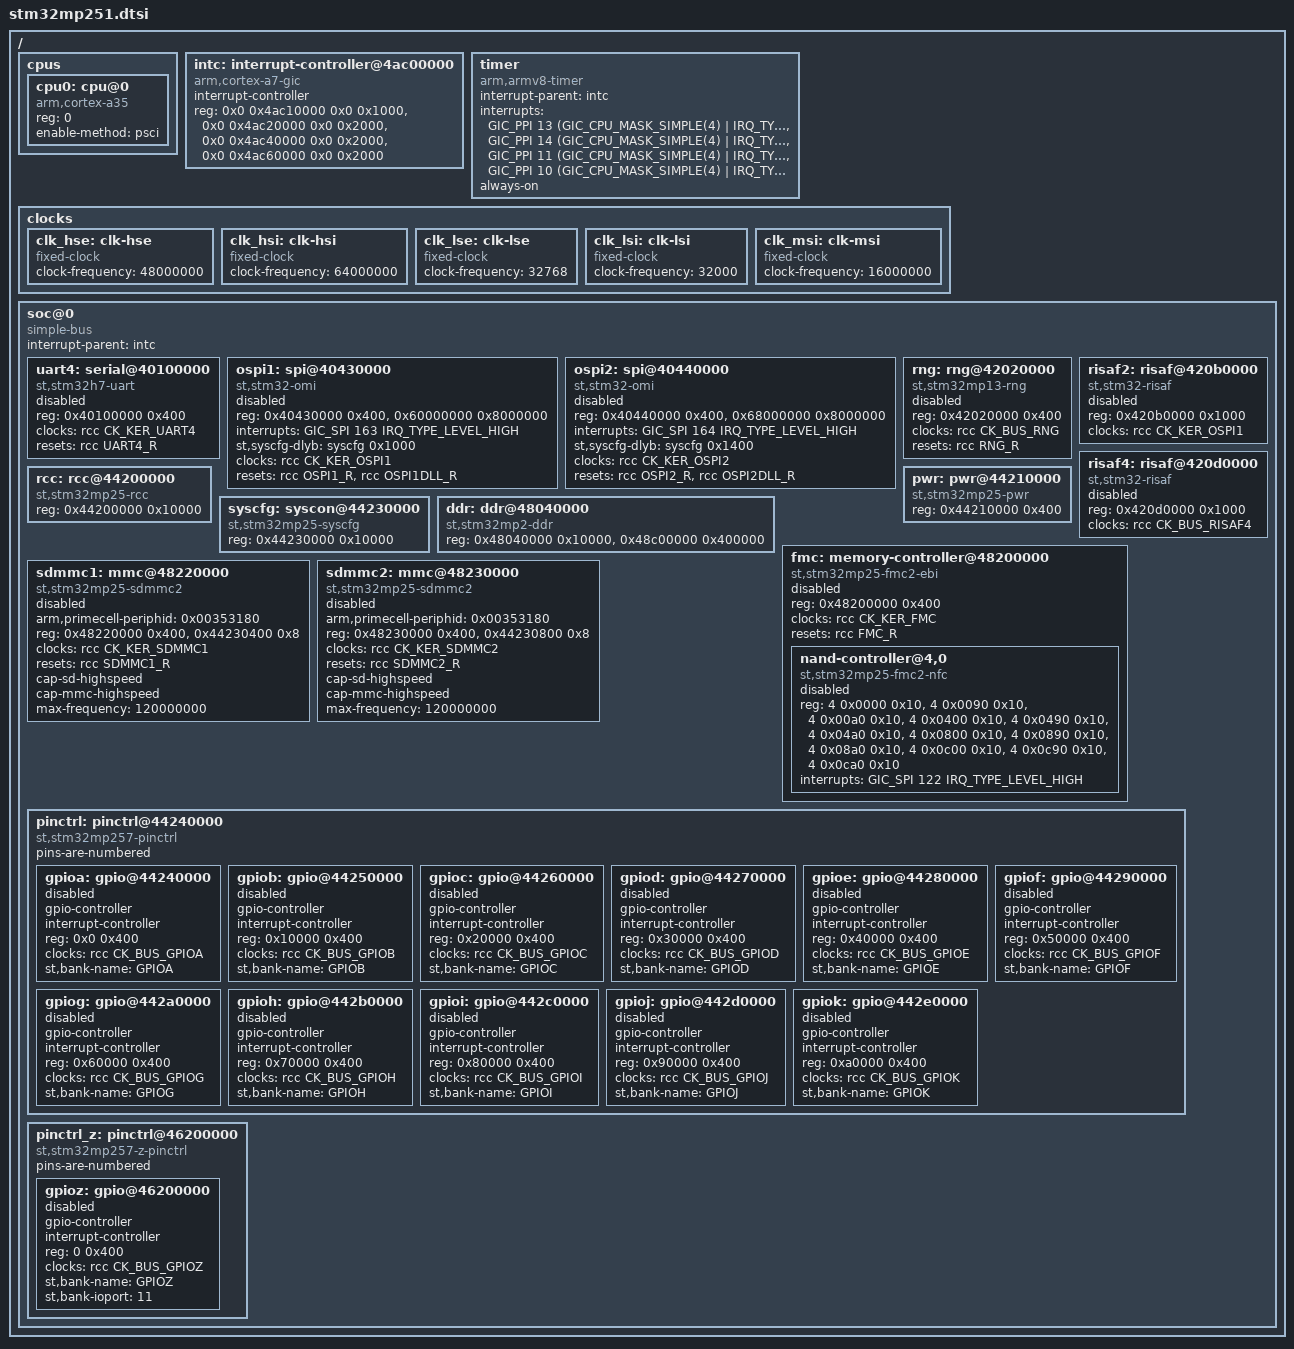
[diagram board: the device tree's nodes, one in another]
// SPDX-License-Identifier: (GPL-2.0+ OR BSD-3-Clause)
/*
 * Copyright (C) STMicroelectronics 2021 - All Rights Reserved
 * Author: Alexandre Torgue <alexandre.torgue@foss.st.com> for STMicroelectronics.
 */

#include <dt-bindings/clock/stm32mp25-clks.h>
#include <dt-bindings/interrupt-controller/arm-gic.h>
#include <dt-bindings/reset/stm32mp25-resets.h>

/ {
	#address-cells = <2>;
	#size-cells = <2>;

	cpus {
		#address-cells = <1>;
		#size-cells = <0>;

		cpu0: cpu@0 {
			compatible = "arm,cortex-a35";
			device_type = "cpu";
			reg = <0>;
			enable-method = "psci";
		};
	};

	intc: interrupt-controller@4ac00000 {
		compatible = "arm,cortex-a7-gic";
		#interrupt-cells = <3>;
		interrupt-controller;
		reg = <0x0 0x4ac10000 0x0 0x1000>,
		      <0x0 0x4ac20000 0x0 0x2000>,
		      <0x0 0x4ac40000 0x0 0x2000>,
		      <0x0 0x4ac60000 0x0 0x2000>;
	};

	timer: timer {
		compatible = "arm,armv8-timer";
		interrupt-parent = <&intc>;
		interrupts = <GIC_PPI 13 (GIC_CPU_MASK_SIMPLE(4) | IRQ_TYPE_LEVEL_LOW)>,
			     <GIC_PPI 14 (GIC_CPU_MASK_SIMPLE(4) | IRQ_TYPE_LEVEL_LOW)>,
			     <GIC_PPI 11 (GIC_CPU_MASK_SIMPLE(4) | IRQ_TYPE_LEVEL_LOW)>,
			     <GIC_PPI 10 (GIC_CPU_MASK_SIMPLE(4) | IRQ_TYPE_LEVEL_LOW)>;
		always-on;
	};

	clocks {
		clk_hse: clk-hse {
			#clock-cells = <0>;
			compatible = "fixed-clock";
			clock-frequency = <48000000>;
		};

		clk_hsi: clk-hsi {
			#clock-cells = <0>;
			compatible = "fixed-clock";
			clock-frequency = <64000000>;
		};

		clk_lse: clk-lse {
			#clock-cells = <0>;
			compatible = "fixed-clock";
			clock-frequency = <32768>;
		};

		clk_lsi: clk-lsi {
			#clock-cells = <0>;
			compatible = "fixed-clock";
			clock-frequency = <32000>;
		};

		clk_msi: clk-msi {
			#clock-cells = <0>;
			compatible = "fixed-clock";
			clock-frequency = <16000000>;
		};
	};

	soc@0 {
		compatible = "simple-bus";
		#address-cells = <1>;
		#size-cells = <1>;
		interrupt-parent = <&intc>;
		ranges = <0x0 0x0 0x0 0x80000000>;

		uart4: serial@40100000 {
			compatible = "st,stm32h7-uart";
			reg = <0x40100000 0x400>;
			clocks = <&rcc CK_KER_UART4>;
			resets = <&rcc UART4_R>;
			status = "disabled";
		};

		ospi1: spi@40430000 {
			compatible = "st,stm32-omi";
			reg = <0x40430000 0x400>, <0x60000000 0x8000000>;
			reg-names = "ospi", "ospi_mm";
			interrupts = <GIC_SPI 163 IRQ_TYPE_LEVEL_HIGH>;
			st,syscfg-dlyb = <&syscfg 0x1000>;
			clocks = <&rcc CK_KER_OSPI1>;
			resets = <&rcc OSPI1_R>, <&rcc OSPI1DLL_R>;
			status = "disabled";
		};

		ospi2: spi@40440000 {
			compatible = "st,stm32-omi";
			reg = <0x40440000 0x400>, <0x68000000 0x8000000>;
			reg-names = "ospi", "ospi_mm";
			interrupts = <GIC_SPI 164 IRQ_TYPE_LEVEL_HIGH>;
			st,syscfg-dlyb = <&syscfg 0x1400>;
			clocks = <&rcc CK_KER_OSPI2>;
			resets = <&rcc OSPI2_R>, <&rcc OSPI2DLL_R>;
			status = "disabled";
		};

		rng: rng@42020000 {
			compatible = "st,stm32mp13-rng";
			reg = <0x42020000 0x400>;
			clocks = <&rcc CK_BUS_RNG>;
			resets = <&rcc RNG_R>;
			status = "disabled";
		};

		risaf2: risaf@420b0000 {
			compatible = "st,stm32-risaf";
			reg = <0x420b0000 0x1000>;
			clocks = <&rcc CK_KER_OSPI1>;
			status = "disabled";
		};

		risaf4: risaf@420d0000 {
			compatible = "st,stm32-risaf";
			reg = <0x420d0000 0x1000>;
			clocks = <&rcc CK_BUS_RISAF4>;
			status = "disabled";
		};

		rcc: rcc@44200000 {
			compatible = "st,stm32mp25-rcc";
			reg = <0x44200000 0x10000>;
			#clock-cells = <1>;
			#reset-cells = <1>;
		};

		pwr: pwr@44210000 {
			compatible = "st,stm32mp25-pwr", "syscon", "simple-mfd";
			reg = <0x44210000 0x400>;
		};

		syscfg: syscon@44230000 {
			compatible = "st,stm32mp25-syscfg", "syscon";
			reg = <0x44230000 0x10000>;
		};

		ddr: ddr@48040000 {
			compatible = "st,stm32mp2-ddr";
			reg = <0x48040000 0x10000>,
			      <0x48c00000 0x400000>;
			status = "okay";
		};

		fmc: memory-controller@48200000 {
			#address-cells = <2>;
			#size-cells = <1>;
			compatible = "st,stm32mp25-fmc2-ebi";
			reg = <0x48200000 0x400>;
			clocks = <&rcc CK_KER_FMC>;
			resets = <&rcc FMC_R>;
			status = "disabled";

			ranges = <0 0 0x70000000 0x04000000>, /* EBI CS 1 */
				 <1 0 0x74000000 0x04000000>, /* EBI CS 2 */
				 <2 0 0x78000000 0x04000000>, /* EBI CS 3 */
				 <3 0 0x7c000000 0x04000000>, /* EBI CS 4 */
				 <4 0 0x48810000 0x00001000>; /* NAND */

			nand-controller@4,0 {
				#address-cells = <1>;
				#size-cells = <0>;
				compatible = "st,stm32mp25-fmc2-nfc";
				reg = <4 0x0000 0x10>,
				      <4 0x0090 0x10>,
				      <4 0x00a0 0x10>,
				      <4 0x0400 0x10>,
				      <4 0x0490 0x10>,
				      <4 0x04a0 0x10>,
				      <4 0x0800 0x10>,
				      <4 0x0890 0x10>,
				      <4 0x08a0 0x10>,
				      <4 0x0c00 0x10>,
				      <4 0x0c90 0x10>,
				      <4 0x0ca0 0x10>;
				interrupts = <GIC_SPI 122 IRQ_TYPE_LEVEL_HIGH>;
				status = "disabled";
			};
		};

		sdmmc1: mmc@48220000 {
			compatible = "st,stm32mp25-sdmmc2", "arm,pl18x", "arm,primecell";
			arm,primecell-periphid = <0x00353180>;
			reg = <0x48220000 0x400>, <0x44230400 0x8>;
			clocks = <&rcc CK_KER_SDMMC1>;
			clock-names = "apb_pclk";
			resets = <&rcc SDMMC1_R>;
			cap-sd-highspeed;
			cap-mmc-highspeed;
			max-frequency = <120000000>;
			status = "disabled";
		};

		sdmmc2: mmc@48230000 {
			compatible = "st,stm32mp25-sdmmc2", "arm,pl18x", "arm,primecell";
			arm,primecell-periphid = <0x00353180>;
			reg = <0x48230000 0x400>, <0x44230800 0x8>;
			clocks = <&rcc CK_KER_SDMMC2>;
			clock-names = "apb_pclk";
			resets = <&rcc SDMMC2_R>;
			cap-sd-highspeed;
			cap-mmc-highspeed;
			max-frequency = <120000000>;
			status = "disabled";
		};

		/*
		 * Break node order to solve dependency probe issue between
		 * pinctrl and exti.
		 */
		pinctrl: pinctrl@44240000 {
			#address-cells = <1>;
			#size-cells = <1>;
			compatible = "st,stm32mp257-pinctrl";
			ranges = <0 0x44240000 0xa0400>;
			pins-are-numbered;

			gpioa: gpio@44240000 {
				gpio-controller;
				#gpio-cells = <2>;
				interrupt-controller;
				#interrupt-cells = <2>;
				reg = <0x0 0x400>;
				clocks = <&rcc CK_BUS_GPIOA>;
				st,bank-name = "GPIOA";
				status = "disabled";
			};

			gpiob: gpio@44250000 {
				gpio-controller;
				#gpio-cells = <2>;
				interrupt-controller;
				#interrupt-cells = <2>;
				reg = <0x10000 0x400>;
				clocks = <&rcc CK_BUS_GPIOB>;
				st,bank-name = "GPIOB";
				status = "disabled";
			};

			gpioc: gpio@44260000 {
				gpio-controller;
				#gpio-cells = <2>;
				interrupt-controller;
				#interrupt-cells = <2>;
				reg = <0x20000 0x400>;
				clocks = <&rcc CK_BUS_GPIOC>;
				st,bank-name = "GPIOC";
				status = "disabled";
			};

			gpiod: gpio@44270000 {
				gpio-controller;
				#gpio-cells = <2>;
				interrupt-controller;
				#interrupt-cells = <2>;
				reg = <0x30000 0x400>;
				clocks = <&rcc CK_BUS_GPIOD>;
				st,bank-name = "GPIOD";
				status = "disabled";
			};

			gpioe: gpio@44280000 {
				gpio-controller;
				#gpio-cells = <2>;
				interrupt-controller;
				#interrupt-cells = <2>;
				reg = <0x40000 0x400>;
				clocks = <&rcc CK_BUS_GPIOE>;
				st,bank-name = "GPIOE";
				status = "disabled";
			};

			gpiof: gpio@44290000 {
				gpio-controller;
				#gpio-cells = <2>;
				interrupt-controller;
				#interrupt-cells = <2>;
				reg = <0x50000 0x400>;
				clocks = <&rcc CK_BUS_GPIOF>;
				st,bank-name = "GPIOF";
				status = "disabled";
			};

			gpiog: gpio@442a0000 {
				gpio-controller;
				#gpio-cells = <2>;
				interrupt-controller;
				#interrupt-cells = <2>;
				reg = <0x60000 0x400>;
				clocks = <&rcc CK_BUS_GPIOG>;
				st,bank-name = "GPIOG";
				status = "disabled";
			};

			gpioh: gpio@442b0000 {
				gpio-controller;
				#gpio-cells = <2>;
				interrupt-controller;
				#interrupt-cells = <2>;
				reg = <0x70000 0x400>;
				clocks = <&rcc CK_BUS_GPIOH>;
				st,bank-name = "GPIOH";
				status = "disabled";
			};

			gpioi: gpio@442c0000 {
				gpio-controller;
				#gpio-cells = <2>;
				interrupt-controller;
				#interrupt-cells = <2>;
				reg = <0x80000 0x400>;
				clocks = <&rcc CK_BUS_GPIOI>;
				st,bank-name = "GPIOI";
				status = "disabled";
			};

			gpioj: gpio@442d0000 {
				gpio-controller;
				#gpio-cells = <2>;
				interrupt-controller;
				#interrupt-cells = <2>;
				reg = <0x90000 0x400>;
				clocks = <&rcc CK_BUS_GPIOJ>;
				st,bank-name = "GPIOJ";
				status = "disabled";
			};

			gpiok: gpio@442e0000 {
				gpio-controller;
				#gpio-cells = <2>;
				interrupt-controller;
				#interrupt-cells = <2>;
				reg = <0xa0000 0x400>;
				clocks = <&rcc CK_BUS_GPIOK>;
				st,bank-name = "GPIOK";
				status = "disabled";
			};
		};

		pinctrl_z: pinctrl@46200000 {
			#address-cells = <1>;
			#size-cells = <1>;
			compatible = "st,stm32mp257-z-pinctrl";
			ranges = <0 0x46200000 0x400>;
			pins-are-numbered;

			gpioz: gpio@46200000 {
				gpio-controller;
				#gpio-cells = <2>;
				interrupt-controller;
				#interrupt-cells = <2>;
				reg = <0 0x400>;
				clocks = <&rcc CK_BUS_GPIOZ>;
				st,bank-name = "GPIOZ";
				st,bank-ioport = <11>;
				status = "disabled";
			};

		};
	};
};
